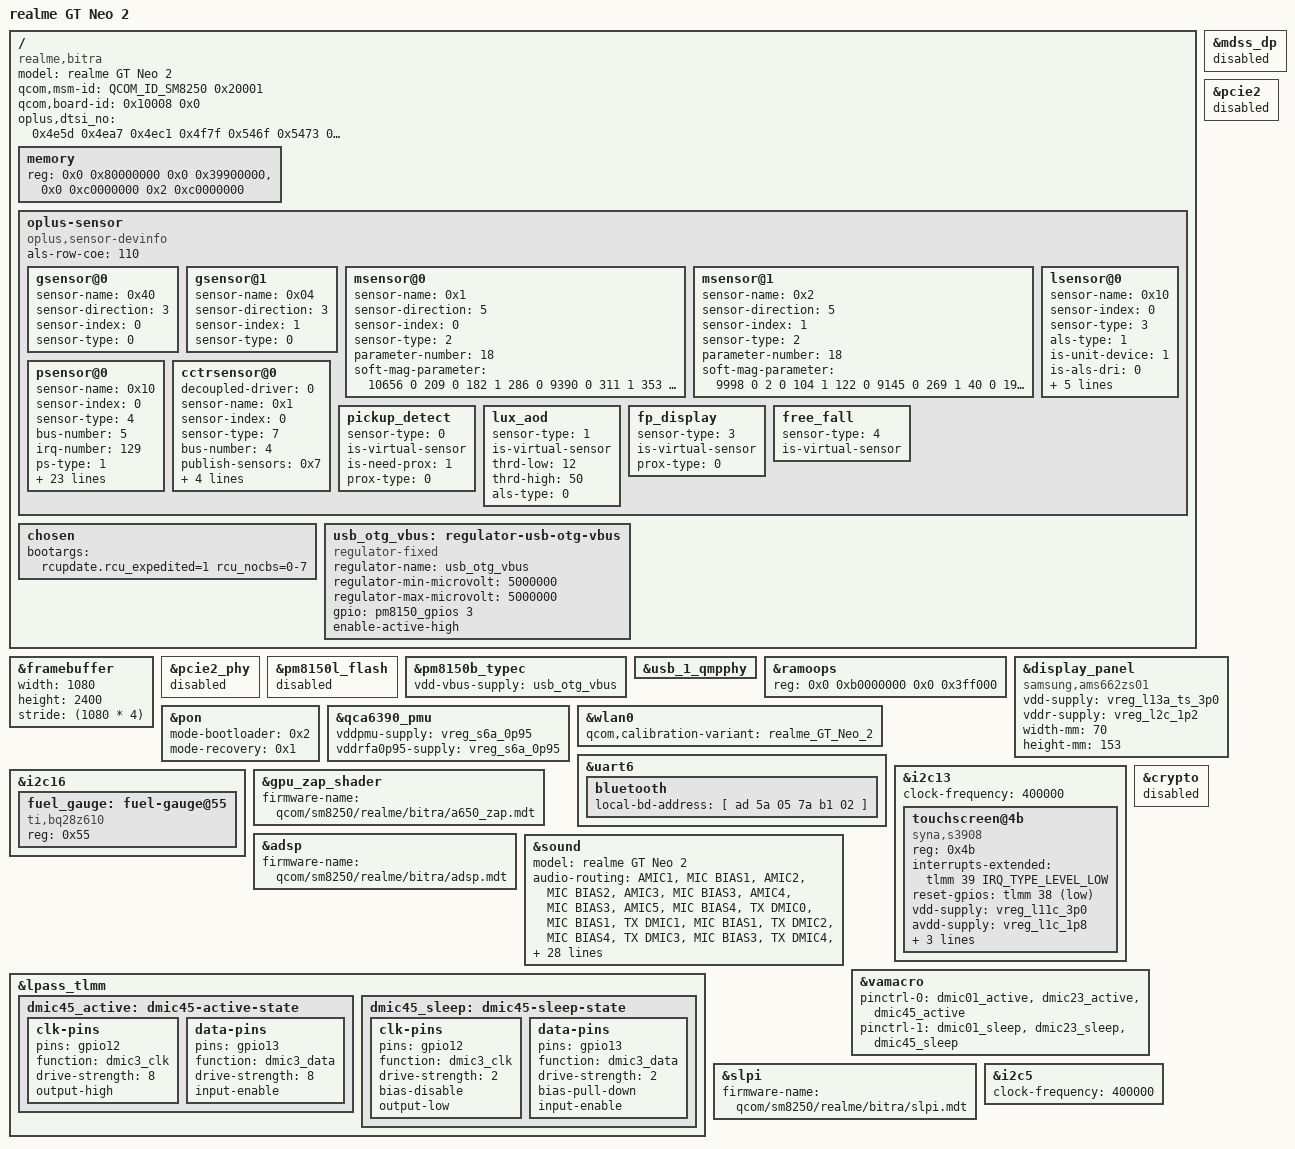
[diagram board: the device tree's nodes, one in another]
// SPDX-License-Identifier: GPL-2.0 OR BSD-3-Clause
/*
 * realme GT Neo 2 (bitra, RMX3366) - stage-1 bring-up tree.
 * Boots from RAM via `fastboot boot` and gives a USB NCM debug shell.
 * Reuses the OnePlus common description: the ABL memory map of this phone
 * is identical (checked against /sys/firmware/fdt of the stock kernel).
 * Everything that can touch persistent storage or needs unported panel
 * drivers is disabled until it has been verified.
 */
#include "sm8250-oneplus-common.dtsi"

/ {
	model = "realme GT Neo 2";
	compatible = "realme,bitra", "qcom,sm8250", "qcom,kona";

	/*
	 * ABL matches the appended DTB on msm-id/board-id and merges the dtbo overlay chosen by
	 * oplus,dtsi_no. Keep these identical to the stock base kona tree (see docs/18).
	 */
	qcom,msm-id = <QCOM_ID_SM8250 0x20001>;
	qcom,board-id = <0x10008 0x0>;
	oplus,dtsi_no = <0x4e5d 0x4ea7 0x4ec1 0x4f7f 0x546f 0x5473 0x5477 0x54e5>;

	/* ABL looks up the node by the exact path /memory; use the layout of the stock kernel (iomem) */
	memory {
		device_type = "memory";
		reg = <0x0 0x80000000 0x0 0x39900000>,
		      <0x0 0xc0000000 0x2 0xc0000000>;
	};

	/*
	 * Sensor inventory the Oplus SLPI firmware reads from SMEM item 130 (oplus-sensor-devinfo driver). Values from the stock
	 * kona-mtp.dtsi (bitra). The SLPI picks the sources that answer on its own I2C/SPI buses.
	 */
	oplus-sensor {
		compatible = "oplus,sensor-devinfo";
		als-row-coe = <110>;
		/*enum {LSM6DSM = 0x01, BMI160 = 0x02, LSM6DS3 = 0x04, BMI260 = 0x08, LSM6DSO = 0x10, ICM4X6XX = 0x20, ICM4X607 = 0x40};*/
		gsensor@0 {
			sensor-name = <0x40>;//icm42607
			sensor-direction = <3>;
			sensor-index = <0>;//source num
			sensor-type = <0>;//OPPO_ACCEL
		};
		gsensor@1 {
			sensor-name = <0x04>;//LSM6DS3C
			sensor-direction = <3>;
			sensor-index = <1>;//source num
			sensor-type = <0>;//OPPO_ACCEL
		};
		/* enum {AKM0991X = 0x01, MMC5603 = 0x02, MXG4300 = 0X04};*/
		msensor@0 {
			sensor-name = <0x1>;//AKM0991X
			sensor-direction = <5>;
			sensor-index = <0>;
			sensor-type = <2>;//OPPO_MAG
			parameter-number= <18>;
			//sensor-parameter = <2>;//0-useless;other- to differ special parameter
			soft-mag-parameter = <10656 0 209 0 182 1 286 0 9390 0 311 1 353 0 85 0 10468 0>;//e00 sign e01 sign ...
		};
		msensor@1 {
			sensor-name = <0x2>;//MMC5603
			sensor-direction = <5>;
			sensor-index = <1>;
			sensor-type = <2>;//OPPO_MAG
			parameter-number= <18>;
			soft-mag-parameter = <9998 0 2 0 104 1 122 0 9145 0 269 1 40 0 195 0 9963 0>;//e00 sign e01 sign ...

		};
		/*enum {STK3A5X = 0x01, TCS3701 = 0x02, TCS3408=0x04, STK3A6X = 0x08, MN78911=0x10};*/
		lsensor@0 {
			sensor-name = <0x10>;//MN78911
			sensor-index = <0>;
			sensor-type = <3>;//OPPO_LIGHT
			als-type = <1>;//<1-normal;2-under screen;3-normal needed compensation>
			is-unit-device = <1>;//<1-alsps unit device;0-separate device>
			is-als-dri = <0>;//<0-polling 1-irq>
			als-factor = <110>;
			is_als_initialed = <0>;
			als_buffer_length = <10>;
			bus-number = <5>;
			irq-number = <129>;
		};
		psensor@0 {
			sensor-name = <0x10>;//MN78911
			sensor-index = <0>;
			sensor-type = <4>;//OPPO_PROXIMITY
			bus-number = <5>;
			irq-number = <129>;
			ps-type = <1>;
			low_step = <300>;
			high_step = <400>;
			low_limit = <700>;
			high_limit = <900>;
			dirty_low_step = <500>;
			dirty_high_step = <700>;
			ps_dirty_limit = <1800>;
			ps_ir_limit = <2000>;
			ps_adjust_min = <0>;
			ps_adjust_max = <1850>;
			sampling_count = <5>;
			step_max = <400>;
			step_min = <100>;
			step_div = <2000>;
			anti_shake_delta = <70>;
			dynamic_cali_max = <4500>;
			raw2offset_radio = <1000>;
			offset_max = <60000>;
			offset_range_min = <0>;//
			offset_range_max = <65534>;
			force_cali_limit = <2000>;
			cali_jitter_limit = <30>;
			cal_offset_margin = <3000>;

		};
		/* enum {tcs3408 = 0x01  stk37600 = 0x02} */
		cctrsensor@0 {
			decoupled-driver = <0>; //0 - tcs3408 driver; 1 - oplus_cct driver
			sensor-name = <0x1>; //tcs3408
			sensor-index = <0>;
			sensor-type = <7>; //OPPO_CCT_REAR
			bus-number = <4>;
			publish-sensors = <0x7>; //bit[0] - als, bit[1] - rgb, bit[2] - flicker
			is-ch-dri = <0>;
			timer-size = <25>; //ms
			fac-cali-sensor = <0x2>; //0x1 - als, 0x2 - rgb, 0x4, flicker
			para-matrix = <3>;//0-default
		};
		/*virtual sensor
		enum sensor_algo_id {
			OPPO_PICKUP_DETECT,
			OPPO_LUX_AOD,
			OPPO_TP_GESTURE,
			OPPO_FP_DISPLAY,
			OPPO_FREE_FALL,
			OPPO_CAMERA_PROTECT,
			SENSOR_ALGO_NUM
		}*/
		pickup_detect {
			sensor-type = <0>;//OPPO_PICKUP_DETECT
			is-virtual-sensor;
			is-need-prox = <1>;//0 - disable; 1 - enable
			prox-type = <0>;//prox_type: 0 - proximity; 1 - proximity_fake
		};
		lux_aod {
			sensor-type = <1>; //OPPO_LUX_AOD
			is-virtual-sensor;
			thrd-low = <12>;
			thrd-high = <50>;
			als-type = <0>; // 0 - ambient_light; 1 - wise_light
		};
		fp_display {
			sensor-type = <3>;//OPPO_FP_DISPLAY
			is-virtual-sensor;
			prox-type = <0>; //  0 - proximity; 1 - proximity_fake
		};
		free_fall {
			sensor-type = <4>;//OPPO_FREE_FALL
			is-virtual-sensor;
		};
	};
};

/delete-node/ &{/memory@80000000};

/ {
	chosen {
		/* ABL rewrites this in place; it refuses trees whose /chosen has no bootargs */
		bootargs = "rcupdate.rcu_expedited=1 rcu_nocbs=0-7";
	};
};

/*
 * No driver binds the bootloader framebuffer node (simplefb/simpledrm are off; msm owns the real display clocks), so its clocks and
 * power domain kept gcc/dispcc from ever reaching sync_state (bootloader votes never released). Keep only the geometry for the efifb console.
 */
&framebuffer {
	/delete-property/ clocks;
	/delete-property/ power-domains;
	width = <1080>;
	height = <2400>;
	stride = <(1080 * 4)>;
};

/* GPU enabled 2026-11-22 (see below); never touch DP, PCIe2 (modem) or remoteprocs until verified; UFS is enabled for the read-only probe; the display pipeline is enabled for the panel bring-up */
&mdss_dp { status = "disabled"; };
&pcie2 { status = "disabled"; };
&pcie2_phy { status = "disabled"; };
&pm8150l_flash { status = "disabled"; };

/* USB: dual-role through the PM8150B Type-C port manager (inherited from the OnePlus 8T tree: usb-role-switch on the DWC3). The debug link used to force "peripheral". */

/*
 * OTG power: on this phone the 5 V VBUS output in host mode comes from the external MP2650 charger (i2c5 @0x5c), switched by the "mps_otg_en"
 * GPIO (pm8150 gpio3, output high = on; stock realme DT: oplus,mp2650-charger), not from the PM8150B VBUS regulator. The Type-C port manager
 * only enables it while the phone is a source (Attached.SRC), never while charging from a host. The driver takes it as the deprecated "vdd-vbus" supply.
 */
/ {
	usb_otg_vbus: regulator-usb-otg-vbus {
		compatible = "regulator-fixed";
		regulator-name = "usb_otg_vbus";
		regulator-min-microvolt = <5000000>;
		regulator-max-microvolt = <5000000>;
		gpio = <&pm8150_gpios 3 GPIO_ACTIVE_HIGH>;
		enable-active-high;
	};
};

&pm8150b_typec {
	vdd-vbus-supply = <&usb_otg_vbus>;
};

&usb_1_qmpphy {
	/delete-property/ mode-switch;
};

/*
 * Match the stock 4.19 ramoops zone layout (it also carves 0x1000 for devinfo) so that
 * after a crash the Droidian kernel can read mainline's console log from /sys/fs/pstore.
 */
&ramoops {
	reg = <0x0 0xb0000000 0x0 0x3ff000>;
};

/* Samsung AMS662ZS01 DSC command-mode panel; wiring from the stock tree (supplies differ from the OnePlus 8T) */
&display_panel {
	compatible = "samsung,ams662zs01";
	vdd-supply = <&vreg_l13a_ts_3p0>;	/* VCI 3.0 V (pm8150_l13) */
	vddr-supply = <&vreg_l2c_1p2>;		/* vendor "vout" rail (pm8150 C ldo2, 1.2 V) */
	width-mm = <70>;
	height-mm = <153>;
	status = "okay";
};

/* reboot reasons through the PMIC PON, so `reboot bootloader` lands in ABL fastboot */
&pon {
	mode-bootloader = <0x2>;
	mode-recovery = <0x1>;
};

/*
 * Wi-Fi/BT PMU: the OnePlus tree takes the 0.95 V PMU rails from PM8009 smpf2, which has no RPMh address on this phone
 * ("could not find RPMh address for resource smpf2"). The stock cnss node powers the chip from pm8150_s6 (aon, 0.95 V),
 * pm8150_s4 (1.8 V io), pm8150_s5 (1.9 V rfa1) and pm8150a_s8 (1.3 V rfa2): use s6 for the two 0.95 V inputs as well.
 */
&qca6390_pmu {
	vddpmu-supply = <&vreg_s6a_0p95>;
	vddrfa0p95-supply = <&vreg_s6a_0p95>;
};

/*
 * Wi-Fi board data: ath11k looks for "bus=pci,qmi-chip-id=0,qmi-board-id=255,variant=realme_GT_Neo_2" in board-2.bin first (the OEM bdwlan.elf of this
 * phone, added with tools/make-ath11k-board.py) and falls back to the generic entry.
 */
&wlan0 {
	qcom,calibration-variant = "realme_GT_Neo_2";
};

/*
 * The QCA6390 comes up with the placeholder address 00:00:00:00:5a:ad, which the kernel treats as "unconfigured".
 * Android keeps the real address in vendor storage (persist); until that is read, use a locally administered one.
 * TEMPORARY: replace with the address read from persist (or generated once and stored).
 */
&uart6 {
	bluetooth {
		local-bd-address = [ ad 5a 05 7a b1 02 ];	/* 02:b1:7a:05:5a:ad, stored little-endian */
	};
};

/*
 * Touchscreen: Synaptics S3908 (TouchComm "oncell"), same address/GPIOs as the OnePlus 8T but different rails:
 * stock vdd = pm8150a_l11 (2.9-3.3 V) = vreg_l11c_3p0, stock vcc (io) = pm8150a_l1 (1.8 V) = vreg_l1c_1p8.
 */
&i2c13 {
	clock-frequency = <400000>;

	status = "okay";

	touchscreen@4b {
		compatible = "syna,s3908";
		reg = <0x4b>;
		interrupts-extended = <&tlmm 39 IRQ_TYPE_LEVEL_LOW>;
		reset-gpios = <&tlmm 38 GPIO_ACTIVE_LOW>;
		vdd-supply = <&vreg_l11c_3p0>;
		avdd-supply = <&vreg_l1c_1p8>;	/* the synaptics_tcm_i2c binding calls the 1.8 V rail avdd (old driver: vcc) */
		wakeup-source;
		pinctrl-0 = <&ts_int_default>;
		pinctrl-1 = <&ts_rst_suspend>;
		pinctrl-names = "default";
	};
};

/*
 * Fuel gauge: TI BQ28Z610 on i2c16 (se16, 0x888000; the stock node is "oplus,bq27541-battery" with qcom,batt_bq28z610), same as the
 * OnePlus 8T. Read-only: charge level, voltage, current, temperature. The charger itself (MP2650 on i2c5, Oplus charge pump,
 * RK826 VOOC MCU on i2c16, SMB1390 on i2c15) has no mainline driver and is not touched; see docs/26-battery-charger.md.
 */
&i2c16 {
	status = "okay";

	fuel_gauge: fuel-gauge@55 {
		compatible = "ti,bq28z610";
		reg = <0x55>;
	};
};

/*
 * The QCE crypto engine has no driver in our config, and its interconnect vote kept qnoc 163d000/1700000 from reaching sync_state
 * (the bootloader's bus bandwidth votes were never released: standby power). Not used, so disable it.
 */
&crypto {
	status = "disabled";
};

/*
 * Adreno 650: sqe/gmu come from linux-firmware (qcom/a650_*), the signed ZAP shader is device specific and comes from the stock vendor
 * firmware of this phone (a650_zap.mdt + .b00-.b02, split MDT layout), installed under /lib/firmware/qcom/sm8250/realme/bitra/.
 */
&gpu_zap_shader {
	firmware-name = "qcom/sm8250/realme/bitra/a650_zap.mdt";
};

/*
 * Audio DSP (ADSP). Firmware from this phone's stock modem partition (image/adsp.mdt + adsp.b00-b18, relocatable, 37 MiB): the reserved-memory
 * map (ADSP at 0x91b00000, 37 MiB) is the stock one, handed over by the bootloader/DTB shim. The other DSPs (CDSP, SLPI) are enabled separately later.
 */
&adsp {
	firmware-name = "qcom/sm8250/realme/bitra/adsp.mdt";
	status = "okay";
};

/*
 * The sound card also lists a DisplayPort playback link whose codec is the DP controller (disabled above): the card would wait for it forever
 * ("DisplayPort Playback: codec dai not found"). Drop it until DisplayPort is brought up.
 */
&sound {
	model = "realme GT Neo 2";
	/* WCD938x mic bias / ADC / DMIC / headphone routing, starting point copied from the OnePlus 8T (same codec); AMIC1..5 -> MIC BIAS routing as in the stock realme DT; stock reads the two analog mics via ADC1 (IN1) and ADC4 (INP5) */
	audio-routing =
		"AMIC1", "MIC BIAS1",
		"AMIC2", "MIC BIAS2",
		"AMIC3", "MIC BIAS3",
		"AMIC4", "MIC BIAS3",
		"AMIC5", "MIC BIAS4",
		"TX DMIC0", "MIC BIAS1",
		"TX DMIC1", "MIC BIAS1",
		"TX DMIC2", "MIC BIAS4",
		"TX DMIC3", "MIC BIAS3",
		"TX DMIC4", "MIC BIAS4",
		"TX DMIC5", "MIC BIAS4",
		"DMIC1", "MIC BIAS1",
		"DMIC2", "MIC BIAS1",
		"DMIC3", "MIC BIAS3",
		"DMIC4", "MIC BIAS3",
		"DMIC5", "MIC BIAS4",
		"DMIC6", "MIC BIAS4",
		"IN1_HPHL", "HPHL_OUT",
		"IN2_HPHR", "HPHR_OUT",
		"IN3_AUX", "AUX_OUT",
		"TX SWR_ADC0", "ADC1_OUTPUT",
		"TX SWR_ADC1", "ADC2_OUTPUT",
		"TX SWR_ADC2", "ADC3_OUTPUT",
		"TX SWR_ADC3", "ADC4_OUTPUT",
		"TX SWR_DMIC0", "DMIC1_OUTPUT",
		"TX SWR_DMIC1", "DMIC2_OUTPUT",
		"TX SWR_DMIC2", "DMIC3_OUTPUT",
		"TX SWR_DMIC3", "DMIC4_OUTPUT",
		"TX SWR_DMIC4", "DMIC5_OUTPUT",
		"TX SWR_DMIC5", "DMIC6_OUTPUT",
		"TX SWR_DMIC6", "DMIC7_OUTPUT",
		"TX SWR_DMIC7", "DMIC8_OUTPUT",
		"RX_TX DEC0_INP", "TX DEC0 MUX",
		"RX_TX DEC1_INP", "TX DEC1 MUX",
		"RX_TX DEC2_INP", "TX DEC2 MUX",
		"RX_TX DEC3_INP", "TX DEC3 MUX",
		"VA DMIC0", "VA MIC BIAS3",
		"VA DMIC1", "VA MIC BIAS3",
		"VA DMIC2", "VA MIC BIAS1",
		"VA DMIC3", "VA MIC BIAS1",
		"VA DMIC4", "VA MIC BIAS4",
		"VA DMIC5", "VA MIC BIAS4",
		"VA SWR_ADC0", "ADC1_OUTPUT",
		"VA SWR_ADC1", "ADC2_OUTPUT",
		"VA SWR_ADC2", "ADC3_OUTPUT",
		"VA SWR_ADC3", "ADC4_OUTPUT",
		"VA SWR_MIC0", "DMIC1_OUTPUT",
		"VA SWR_MIC1", "DMIC2_OUTPUT",
		"VA SWR_MIC2", "DMIC3_OUTPUT",
		"VA SWR_MIC3", "DMIC4_OUTPUT",
		"VA SWR_MIC4", "DMIC5_OUTPUT",
		"VA SWR_MIC5", "DMIC6_OUTPUT",
		"VA SWR_MIC6", "DMIC7_OUTPUT",
		"VA SWR_MIC7", "DMIC8_OUTPUT";
	/delete-node/ displayport-dai-link;
};

/*
 * The stock realme DT enables three DMIC pin pairs (gpio6/7, gpio8/9 and gpio12/13) and its three-microphone setups use DMIC1, DMIC3 and
 * DMIC4; the OnePlus common file only configures the first two. Add the third pair and route the VA DMIC supplies as the stock DT does.
 */
&lpass_tlmm {
	dmic45_active: dmic45-active-state {
		clk-pins {
			pins = "gpio12";
			function = "dmic3_clk";
			drive-strength = <8>;
			output-high;
		};

		data-pins {
			pins = "gpio13";
			function = "dmic3_data";
			drive-strength = <8>;
			input-enable;
		};
	};

	dmic45_sleep: dmic45-sleep-state {
		clk-pins {
			pins = "gpio12";
			function = "dmic3_clk";
			drive-strength = <2>;
			bias-disable;
			output-low;
		};

		data-pins {
			pins = "gpio13";
			function = "dmic3_data";
			drive-strength = <2>;
			bias-pull-down;
			input-enable;
		};
	};
};

&vamacro {
	pinctrl-0 = <&dmic01_active>, <&dmic23_active>, <&dmic45_active>;
	pinctrl-1 = <&dmic01_sleep>, <&dmic23_sleep>, <&dmic45_sleep>;
	pinctrl-names = "default", "sleep";
};

/* Sensor DSP (SLPI): firmware extracted from the stock modem partition (tools/extract-dsp-firmware.py), memory region from the OnePlus common DT */
&slpi {
	firmware-name = "qcom/sm8250/realme/bitra/slpi.mdt";
	status = "okay";
};

/*
 * i2c5 carries the MP2650 main charger (@0x5c; stock: oplus,mp2650-charger, 400 kHz). No driver binds it: the bus is enabled so that its
 * registers can be read (read-only, i2c-dev) to see what the bootloader programmed (docs/26).
 */
&i2c5 {
	clock-frequency = <400000>;
	status = "okay";
};
